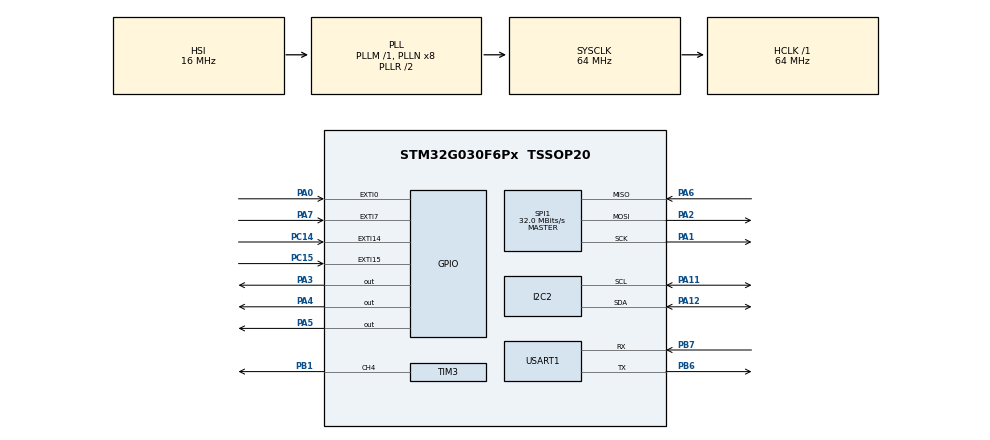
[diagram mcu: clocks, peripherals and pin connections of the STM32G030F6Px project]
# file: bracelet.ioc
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Dma.Request0=TIM3_CH4
Dma.TIM3_CH4.0.Direction=DMA_MEMORY_TO_PERIPH
Dma.TIM3_CH4.0.EventEnable=DISABLE
Dma.TIM3_CH4.0.Instance=DMA1_Channel1
Dma.TIM3_CH4.0.MemDataAlignment=DMA_MDATAALIGN_WORD
Dma.TIM3_CH4.0.MemInc=DMA_MINC_ENABLE
Dma.TIM3_CH4.0.Mode=DMA_CIRCULAR
Dma.TIM3_CH4.0.PeriphDataAlignment=DMA_PDATAALIGN_WORD
Dma.TIM3_CH4.0.PeriphInc=DMA_PINC_DISABLE
Dma.TIM3_CH4.0.Polarity=HAL_DMAMUX_REQ_GEN_RISING
Dma.TIM3_CH4.0.Priority=DMA_PRIORITY_LOW
Dma.TIM3_CH4.0.RequestNumber=1
Dma.TIM3_CH4.0.SignalID=NONE
Dma.TIM3_CH4.0.SyncEnable=DISABLE
Dma.TIM3_CH4.0.SyncPolarity=HAL_DMAMUX_SYNC_NO_EVENT
Dma.TIM3_CH4.0.SyncRequestNumber=1
Dma.TIM3_CH4.0.SyncSignalID=NONE
I2C2.Timing=0x10B17DB5
Mcu.Family=STM32G0
Mcu.Name=STM32G030F6Px
Mcu.Package=TSSOP20
NVIC.DMA1_Channel1_IRQn=true\:0\:0\:false\:false\:true\:false\:true\:true
PA0.Signal=GPXTI0
PA1.Mode=Full_Duplex_Master
PA1.Signal=SPI1_SCK
PA11\ [PA9].Mode=I2C
PA11\ [PA9].Signal=I2C2_SCL
PA12\ [PA10].Mode=I2C
PA12\ [PA10].Signal=I2C2_SDA
PA13.Mode=Serial_Wire
PA13.Signal=SYS_SWDIO
PA14-BOOT0.Mode=Serial_Wire
PA14-BOOT0.Signal=SYS_SWCLK
PA14-BOOT0__PA15.StandardMode=true
PA2.Mode=Full_Duplex_Master
PA2.Signal=SPI1_MOSI
PA3.Signal=GPIO_Output
PA4.Signal=GPIO_Output
PA5.Signal=GPIO_Output
PA6.Mode=Full_Duplex_Master
PA6.Signal=SPI1_MISO
PA7.Signal=GPXTI7
PB0__PB1__PB2__PA8.StandardMode=true
PB1.Signal=S_TIM3_CH4
PB3__PB4__PB5__PB6.StandardMode=true
PB6.Mode=Asynchronous
PB6.Signal=USART1_TX
PB7.Mode=Asynchronous
PB7.Signal=USART1_RX
PB7__PB8.StandardMode=true
PC14-OSC32_IN\ (PC14).Signal=GPXTI14
PC14-OSC32_IN\ (PC14)__PB9.StandardMode=true
PC15-OSC32_OUT\ (PC15).Signal=GPXTI15
ProjectManager.HeapSize=0x200
ProjectManager.StackSize=0x400
ProjectManager.TargetToolchain=MDK-ARM V5.32
RCC.ADCFreq_Value=64000000
RCC.AHBFreq_Value=64000000
RCC.CortexFreq_Value=64000000
RCC.EXTERNAL_CLOCK_VALUE=12288000
RCC.HCLKFreq_Value=64000000
RCC.HSE_VALUE=8000000
RCC.HSI_VALUE=16000000
RCC.LSE_VALUE=32768
RCC.SYSCLKFreq_VALUE=64000000
RCC.SYSCLKSource=RCC_SYSCLKSOURCE_PLLCLK
RCC.VCOOutputFreq_Value=128000000
SH.S_TIM3_CH4.0=TIM3_CH4,PWM Generation4 CH4
SPI1.BaudRatePrescaler=SPI_BAUDRATEPRESCALER_2
SPI1.CalculateBaudRate=32.0 MBits/s
SPI1.Direction=SPI_DIRECTION_2LINES
SPI1.Mode=SPI_MODE_MASTER
SPI1.VirtualType=VM_MASTER
TIM3.AutoReloadPreload=TIM_AUTORELOAD_PRELOAD_ENABLE
TIM3.Channel-PWM\ Generation4\ CH4=TIM_CHANNEL_4
TIM3.Period=79
USART1.VirtualMode-Asynchronous=VM_ASYNC
board=custom

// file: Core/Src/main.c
/* USER CODE BEGIN Header */
/**
  ******************************************************************************
  * @file           : main.c
  * @brief          : Main program body
  ******************************************************************************
  * @attention
  *
  * Copyright (c) 2025 STMicroelectronics.
  * All rights reserved.
  *
  * This software is licensed under terms that can be found in the LICENSE file
  * in the root directory of this software component.
  * If no LICENSE file comes with this software, it is provided AS-IS.
  *
  ******************************************************************************
  */
/* USER CODE END Header */
#include "main.h"
#include "dma.h"
#include "i2c.h"
#include "spi.h"
#include "tim.h"
#include "usart.h"
#include "gpio.h"

/* USER CODE BEGIN Includes */
#include "RGB.h"
/* USER CODE END Includes */

void SystemClock_Config(void);

int main(void)
{

  /* MCU Configuration--------------------------------------------------------*/

  /* Reset of all peripherals, Initializes the Flash interface and the Systick. */
  HAL_Init();

  /* Configure the system clock */
  SystemClock_Config();

  /* Initialize all configured peripherals */
  MX_GPIO_Init();
  MX_DMA_Init();
  MX_SPI1_Init();
  MX_TIM3_Init();
  MX_I2C2_Init();
  MX_USART1_UART_Init();
  /* USER CODE BEGIN 2 */
  RGB_Test();
  /* USER CODE END 2 */

  /* Infinite loop */
  while (1)
  {

  }
}

void SystemClock_Config(void)
{
  RCC_OscInitTypeDef RCC_OscInitStruct = {0};
  RCC_ClkInitTypeDef RCC_ClkInitStruct = {0};

  /** Configure the main internal regulator output voltage
  */
  HAL_PWREx_ControlVoltageScaling(PWR_REGULATOR_VOLTAGE_SCALE1);

  /** Initializes the RCC Oscillators according to the specified parameters
  * in the RCC_OscInitTypeDef structure.
  */
  RCC_OscInitStruct.OscillatorType = RCC_OSCILLATORTYPE_HSI;
  RCC_OscInitStruct.HSIState = RCC_HSI_ON;
  RCC_OscInitStruct.HSIDiv = RCC_HSI_DIV1;
  RCC_OscInitStruct.HSICalibrationValue = RCC_HSICALIBRATION_DEFAULT;
  RCC_OscInitStruct.PLL.PLLState = RCC_PLL_ON;
  RCC_OscInitStruct.PLL.PLLSource = RCC_PLLSOURCE_HSI;
  RCC_OscInitStruct.PLL.PLLM = RCC_PLLM_DIV1;
  RCC_OscInitStruct.PLL.PLLN = 8;
  RCC_OscInitStruct.PLL.PLLP = RCC_PLLP_DIV2;
  RCC_OscInitStruct.PLL.PLLR = RCC_PLLR_DIV2;
  if (HAL_RCC_OscConfig(&RCC_OscInitStruct) != HAL_OK)
  {
    Error_Handler();
  }

  /** Initializes the CPU, AHB and APB buses clocks
  */
  RCC_ClkInitStruct.ClockType = RCC_CLOCKTYPE_HCLK|RCC_CLOCKTYPE_SYSCLK
                              |RCC_CLOCKTYPE_PCLK1;
  RCC_ClkInitStruct.SYSCLKSource = RCC_SYSCLKSOURCE_PLLCLK;
  RCC_ClkInitStruct.AHBCLKDivider = RCC_SYSCLK_DIV1;
  RCC_ClkInitStruct.APB1CLKDivider = RCC_HCLK_DIV1;

  if (HAL_RCC_ClockConfig(&RCC_ClkInitStruct, FLASH_LATENCY_2) != HAL_OK)
  {
    Error_Handler();
  }
}

void Error_Handler(void)
{
  __disable_irq();
  while (1)
  {
  }
}
